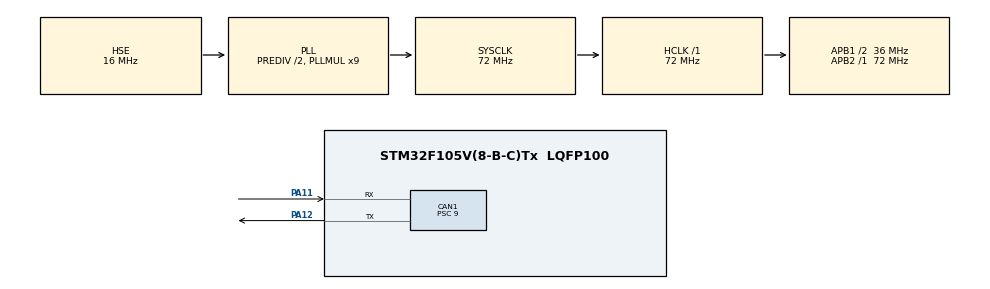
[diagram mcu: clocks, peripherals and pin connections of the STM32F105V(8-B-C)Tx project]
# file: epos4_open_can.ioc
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CAN1.ABOM=ENABLE
CAN1.AWUM=ENABLE
CAN1.BS1=CAN_BS1_6TQ
CAN1.CalculateBaudRate=500000
CAN1.CalculateTimeBit=2000
CAN1.CalculateTimeQuantum=250.0
CAN1.NART=ENABLE
CAN1.Prescaler=9
CAN1.TXFP=ENABLE
Mcu.Family=STM32F1
Mcu.Name=STM32F105V(8-B-C)Tx
Mcu.Package=LQFP100
NVIC.CAN1_RX0_IRQn=true\:0\:0\:false\:false\:true\:true\:true\:true
NVIC.PriorityGroup=NVIC_PRIORITYGROUP_4
NVIC.TIM2_IRQn=true\:15\:0\:false\:false\:true\:false\:true\:true
NVIC.TimeBase=TIM2_IRQn
NVIC.TimeBaseIP=TIM2
OSC_IN.Mode=HSE-External-Oscillator
OSC_IN.Signal=RCC_OSC_IN
OSC_OUT.Mode=HSE-External-Oscillator
OSC_OUT.Signal=RCC_OSC_OUT
PA11.Mode=CAN_Activate
PA11.Signal=CAN1_RX
PA12.Mode=CAN_Activate
PA12.Signal=CAN1_TX
PA13.Mode=Serial_Wire
PA13.Signal=SYS_JTMS-SWDIO
PA14.Mode=Serial_Wire
PA14.Signal=SYS_JTCK-SWCLK
ProjectManager.HeapSize=0x400
ProjectManager.StackSize=0x800
ProjectManager.TargetToolchain=CMake
RCC.AHBFreq_Value=72000000
RCC.APB1CLKDivider=RCC_HCLK_DIV2
RCC.APB1Freq_Value=36000000
RCC.APB1TimFreq_Value=72000000
RCC.APB2Freq_Value=72000000
RCC.APB2TimFreq_Value=72000000
RCC.HCLKFreq_Value=72000000
RCC.HSEDivPLL=RCC_HSE_PREDIV_DIV2
RCC.HSE_VALUE=16000000
RCC.PLLMUL=RCC_PLL_MUL9
RCC.PLLSourceVirtual=RCC_PLLSOURCE_HSE
RCC.SYSCLKFreq_VALUE=72000000
RCC.SYSCLKSource=RCC_SYSCLKSOURCE_PLLCLK
RCC.USBFreq_Value=48000000
VP_SYS_VS_tim2.Mode=TIM2
board=custom

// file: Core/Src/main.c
/* USER CODE BEGIN Header */
/**
  ******************************************************************************
  * @file           : main.c
  * @brief          : Main program body
  ******************************************************************************
  * @attention
  *
  * Copyright (c) 2026 STMicroelectronics.
  * All rights reserved.
  *
  * This software is licensed under terms that can be found in the LICENSE file
  * in the root directory of this software component.
  * If no LICENSE file comes with this software, it is provided AS-IS.
  *
  ******************************************************************************
  */
/* USER CODE END Header */
#include "main.h"

/* USER CODE BEGIN Includes */
#include "app.h"

/* USER CODE END Includes */

CAN_HandleTypeDef hcan1;

void SystemClock_Config(void);
static void MX_GPIO_Init(void);
static void MX_CAN1_Init(void);

int main(void)
{

  /* MCU Configuration--------------------------------------------------------*/

  /* Reset of all peripherals, Initializes the Flash interface and the Systick. */
  HAL_Init();

  /* Configure the system clock */
  SystemClock_Config();

  /* Initialize all configured peripherals */
  MX_GPIO_Init();
  MX_CAN1_Init();
  /* USER CODE BEGIN 2 */
  App_main();

  /* USER CODE END 2 */

  /* Infinite loop */
  while (1)
  {

  }
}

void SystemClock_Config(void)
{
  RCC_OscInitTypeDef RCC_OscInitStruct = {0};
  RCC_ClkInitTypeDef RCC_ClkInitStruct = {0};

  /** Initializes the RCC Oscillators according to the specified parameters
  * in the RCC_OscInitTypeDef structure.
  */
  RCC_OscInitStruct.OscillatorType = RCC_OSCILLATORTYPE_HSE;
  RCC_OscInitStruct.HSEState = RCC_HSE_ON;
  RCC_OscInitStruct.HSEPredivValue = RCC_HSE_PREDIV_DIV2;
  RCC_OscInitStruct.HSIState = RCC_HSI_ON;
  RCC_OscInitStruct.Prediv1Source = RCC_PREDIV1_SOURCE_HSE;
  RCC_OscInitStruct.PLL.PLLState = RCC_PLL_ON;
  RCC_OscInitStruct.PLL.PLLSource = RCC_PLLSOURCE_HSE;
  RCC_OscInitStruct.PLL.PLLMUL = RCC_PLL_MUL9;
  RCC_OscInitStruct.PLL2.PLL2State = RCC_PLL_NONE;
  if (HAL_RCC_OscConfig(&RCC_OscInitStruct) != HAL_OK)
  {
    Error_Handler();
  }

  /** Initializes the CPU, AHB and APB buses clocks
  */
  RCC_ClkInitStruct.ClockType = RCC_CLOCKTYPE_HCLK|RCC_CLOCKTYPE_SYSCLK
                              |RCC_CLOCKTYPE_PCLK1|RCC_CLOCKTYPE_PCLK2;
  RCC_ClkInitStruct.SYSCLKSource = RCC_SYSCLKSOURCE_PLLCLK;
  RCC_ClkInitStruct.AHBCLKDivider = RCC_SYSCLK_DIV1;
  RCC_ClkInitStruct.APB1CLKDivider = RCC_HCLK_DIV2;
  RCC_ClkInitStruct.APB2CLKDivider = RCC_HCLK_DIV1;

  if (HAL_RCC_ClockConfig(&RCC_ClkInitStruct, FLASH_LATENCY_2) != HAL_OK)
  {
    Error_Handler();
  }

  /** Configure the Systick interrupt time
  */
  __HAL_RCC_PLLI2S_ENABLE();
}

static void MX_CAN1_Init(void)
{

  hcan1.Instance = CAN1;
  hcan1.Init.Prescaler = 9;
  hcan1.Init.Mode = CAN_MODE_NORMAL;
  hcan1.Init.SyncJumpWidth = CAN_SJW_1TQ;
  hcan1.Init.TimeSeg1 = CAN_BS1_6TQ;
  hcan1.Init.TimeSeg2 = CAN_BS2_1TQ;
  hcan1.Init.TimeTriggeredMode = DISABLE;
  hcan1.Init.AutoBusOff = ENABLE;
  hcan1.Init.AutoWakeUp = ENABLE;
  hcan1.Init.AutoRetransmission = ENABLE;
  hcan1.Init.ReceiveFifoLocked = DISABLE;
  hcan1.Init.TransmitFifoPriority = ENABLE;
  if (HAL_CAN_Init(&hcan1) != HAL_OK)
  {
    Error_Handler();
  }

}

static void MX_GPIO_Init(void)
{

  /* GPIO Ports Clock Enable */
  __HAL_RCC_GPIOA_CLK_ENABLE();

}

void HAL_TIM_PeriodElapsedCallback(TIM_HandleTypeDef *htim)
{
  if (htim->Instance == TIM2)
  {
    HAL_IncTick();
  }
}

void Error_Handler(void)
{
  __disable_irq();
  while (1)
  {
  }
}
